# AUX_TDC register map
Vendor: Texas Instruments
Peripheral module from a debugger description file (folder CC26x4).
Registers are 32-bit, access per field, reset 0x0 unless marked. A register's access mark holds for its fields unless they carry their own. Offsets are as the file gives them; lines under a group give offsets from that group; [hi:lo] are bit positions; {n}, {i} and the like mark numbered series; 'fields as' and 'values as' point back to an identical list; <NAME> marks a mode.

## AUX_TDC — AUX Time To Digital Converter (AUX_TDC) is used to measure the time between two events with high resolution. AUX_TDC consists of a state machine that operates at AUX bus rate and an asynchronous fast-counter which is clocked by the TDC clock. DDI_0_OSC:CTL0.ACLK_TDC_SRC_SEL configures TDC clock source. The fast-counter counts on both edges of the TDC clock to double the resolution. See the Technical Reference Manual for event timing requirements.
0x00 CTL — Control
  [1:0] CMD wo — TDC commands.
    3=ABORT (Force TDC state machine back to IDLE state. Never write this command while AUX_TDC:STAT.STATE equals CLR_CNT or WAIT_CLR_CNT_DONE.); 2=RUN (Asynchronous counter start. The counter starts to count when the start event is high. To achieve precise edge-to-edge measurements you must ensure that the start event is low for at least 420 ns after you write this command.); 1=RUN_SYNC_START (Synchronous counter start. The counter looks for the opposite edge of the selected start event before it starts to count when the selected edge occurs. This guarantees an edge-triggered start and is recommended for frequency measurements.); 0=CLR_RESULT (Clear STAT.SAT, STAT.DONE, and RESULT.VALUE. This is not needed as prerequisite for a measurement. Reliable clear is only guaranteed from IDLE state.)
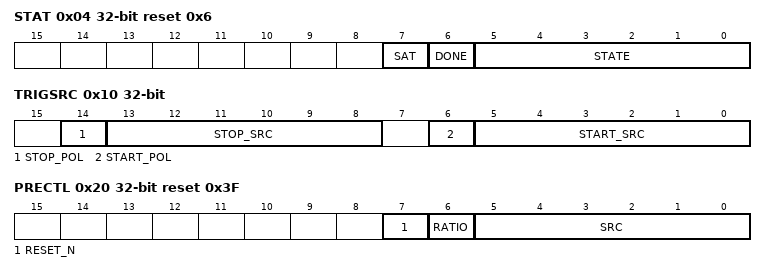
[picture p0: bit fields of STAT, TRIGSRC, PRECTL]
0x04 STAT ro reset 0x6 — Status
  [7] SAT — TDC measurement saturation flag. 0: Conversion has not saturated. 1: Conversion stopped due to saturation. This field is cleared when a new measurement is started or when CLR_RESULT is written to CTL.CMD.
  [6] DONE — TDC measurement complete flag. 0: TDC measurement has not yet completed. 1: TDC measurement has completed. This field clears when a new TDC measurement starts or when you write CLR_RESULT to CTL.CMD.
  [5:0] STATE — TDC state machine status.
    46=FORCE_STOP (Current state is TDC_FORCESTOP. You wrote ABORT to CTL.CMD to abort the TDC measurement.); 30=START_FALL (Current state is TDC_WAIT_STARTFALL. The fast-counter circuit waits for a falling edge on the start event.); 22=WAIT_CLR_CNT_DONE (Current state is TDC_STATE_WAIT_CLRCNT_DONE. The state machine waits for fast-counter circuit to finish reset.); 15=POR (Current state is TDC_STATE_POR. This is the reset state.); 14=GET_RESULT (Current state is TDC_STATE_GETRESULTS. The state machine copies the counter value from the fast-counter circuit.); 12=WAIT_STOP_CNTDWN (Current state is TDC_STATE_WAIT_STOPCNTDOWN. The fast-counter circuit looks for the stop condition. It will ignore a number of stop events configured in TRIGCNTLOAD.CNT.); 8=WAIT_STOP (Current state is TDC_STATE_WAIT_STOP. The state machine waits for the fast-counter circuit to stop.); 7=CLR_CNT (Current state is TDC_STATE_CLRCNT. The fast-counter circuit is reset.); 6=IDLE (Current state is TDC_STATE_IDLE. This is the default state after reset and abortion. State will change when you write CTL.CMD to either RUN_SYNC_START or RUN.); 4=WAIT_START_STOP_CNT_EN (Current state is TDC_STATE_WAIT_STARTSTOPCNTEN. The fast-counter circuit looks for the start condition. The state machine waits for the fast-counter to increment.); 0=WAIT_START (Current state is TDC_STATE_WAIT_START. The fast-counter circuit looks for the start condition. The state machine waits for the fast-counter to increment.)
0x08 RESULT ro reset 0x2 — Result Result of last TDC conversion.
  [24:0] VALUE — TDC conversion result. The result of the TDC conversion is given in number of clock edges of the clock source selected in DDI_0_OSC:CTL0.ACLK_TDC_SRC_SEL. Both rising and falling edges are counted. If TDC counter saturates, VALUE is slightly higher than SATCFG.LIMIT, as it takes a non-zero time to stop the measurement. Hence, the maximum value of this field becomes slightly higher than 2^24 if you configure SATCFG.LIMIT to R24.
0x0C SATCFG reset 0xF — Saturation Configuration
  [3:0] LIMIT rw — Saturation limit. The flag STAT.SAT is set when the TDC counter saturates. Values not enumerated are not supported
    {v}=R{v+9} (Result bit {v+9}: TDC conversion saturates and stops when RESULT.VALUE[{v+9}] is set.) (v=3..15)
0x10 TRIGSRC — Trigger Source Select source and polarity for TDC start and stop events. See the Technical Reference Manual for event timing requirements.
  [14] STOP_POL rw — Polarity of stop source. Change only while STAT.STATE is IDLE.
    1=LOW (TDC conversion stops when low level is detected.); 0=HIGH (TDC conversion stops when high level is detected.)
  [13:8] STOP_SRC rw — Select stop source from the asynchronous AUX event bus. Change only while STAT.STATE is IDLE.
    63=NO_EVENT; 62=AUX_TDC_PRE (Select TDC Prescaler event which is generated by configuration of PRECTL.); 61=AUX_SMPH_AUTOTAKE_DONE (AUX_EVCTL:EVSTAT3.AUX_SMPH_AUTOTAKE_DONE); 60=AUX_ADC_FIFO_NOT_EMPTY (AUX_EVCTL:EVSTAT3.AUX_ADC_FIFO_NOT_EMPTY); 59=AUX_ADC_FIFO_ALMOST_FULL (AUX_EVCTL:EVSTAT3.AUX_ADC_FIFO_ALMOST_FULL); 58=AUX_ADC_IRQ (AUX_EVCTL:EVSTAT3.AUX_ADC_IRQ); 57=AUX_ADC_DONE (AUX_EVCTL:EVSTAT3.AUX_ADC_DONE); 56=AUX_ISRC_RESET_N (AUX_EVCTL:EVSTAT3.AUX_ISRC_RESET_N); 55=AUX_TDC_DONE (AUX_EVCTL:EVSTAT3.AUX_TDC_DONE); 54=AUX_TIMER0_EV (AUX_EVCTL:EVSTAT3.AUX_TIMER0_EV); 53=AUX_TIMER1_EV (AUX_EVCTL:EVSTAT3.AUX_TIMER1_EV); 52=AUX_TIMER2_PULSE (AUX_EVCTL:EVSTAT3.AUX_TIMER2_PULSE); {v}=AUX_TIMER2_EV{v-48} (AUX_EVCTL:EVSTAT3.AUX_TIMER2_EV{v-48}) (v=48..51); 47=AUX_COMPB (AUX_EVCTL:EVSTAT2.AUX_COMPB); 46=AUX_COMPA (AUX_EVCTL:EVSTAT2.AUX_COMPA); 45=MCU_OBSMUX1 (AUX_EVCTL:EVSTAT2.MCU_OBSMUX1); 44=MCU_OBSMUX0 (AUX_EVCTL:EVSTAT2.MCU_OBSMUX0); 43=MCU_EV (AUX_EVCTL:EVSTAT2.MCU_EV); 42=ACLK_REF (AUX_EVCTL:EVSTAT2.ACLK_REF); 41=VDDR_RECHARGE (AUX_EVCTL:EVSTAT2.VDDR_RECHARGE); 40=MCU_ACTIVE (AUX_EVCTL:EVSTAT2.MCU_ACTIVE); 39=PWR_DWN (AUX_EVCTL:EVSTAT2.PWR_DWN); 38=SCLK_LF (AUX_EVCTL:EVSTAT2.SCLK_LF); 37=AON_BATMON_TEMP_UPD (AUX_EVCTL:EVSTAT2.AON_BATMON_TEMP_UPD); 36=AON_BATMON_BAT_UPD (AUX_EVCTL:EVSTAT2.AON_BATMON_BAT_UPD); 35=AON_RTC_4KHZ (AUX_EVCTL:EVSTAT2.AON_RTC_4KHZ); 34=AON_RTC_CH2_DLY (AUX_EVCTL:EVSTAT2.AON_RTC_CH2_DLY); 33=AON_RTC_CH2 (AUX_EVCTL:EVSTAT2.AON_RTC_CH2); 32=MANUAL_EV (AUX_EVCTL:EVSTAT2.MANUAL_EV); {v}=AUXIO{v} (AUX_EVCTL:EVSTAT1.AUXIO{v}) (v=16..31); {v}=AUXIO{v} (AUX_EVCTL:EVSTAT0.AUXIO{v}) (v=0..15)
  [6] START_POL rw — Polarity of start source. Change only while STAT.STATE is IDLE.
    1=LOW (TDC conversion starts when low level is detected.); 0=HIGH (TDC conversion starts when high level is detected.)
  [5:0] START_SRC rw — Select start source from the asynchronous AUX event bus. Change only while STAT.STATE is IDLE.
    values as STOP_SRC
0x14 TRIGCNT — Trigger Counter Stop-counter control and status.
  [15:0] CNT rw — Number of stop events to ignore when AUX_TDC:TRIGCNTCFG.EN is 1. Read CNT to get the remaining number of stop events to ignore during a TDC measurement. Write CNT to update the remaining number of stop events to ignore during a TDC measurement. The TDC measurement ignores updates of CNT if there are no more stop events left to ignore. When AUX_TDC:TRIGCNTCFG.EN is 1, TRIGCNTLOAD.CNT is loaded into CNT at the start of the measurement.
0x18 TRIGCNTLOAD — Trigger Counter Load Stop-counter load.
  [15:0] CNT rw — Number of stop events to ignore when AUX_TDC:TRIGCNTCFG.EN is 1. To measure frequency of an event source: - Set start event equal to stop event. - Set CNT to number of periods to measure. Both 0 and 1 values measures a single event source period. To measure pulse width of an event source: - Set start event source equal to stop event source. - Select different polarity for start and stop event. - Set CNT to 0. To measure time from the start event to the Nth stop event when N > 1: - Select different start and stop event source. - Set CNT to (N-1). See the Technical Reference Manual for event timing requirements. When AUX_TDC:TRIGCNTCFG.EN is 1, CNT is loaded into TRIGCNT.CNT at the start of the measurement.
0x1C TRIGCNTCFG — Trigger Counter Configuration Stop-counter configuration.
  [0] EN rw — Enable stop-counter. 0: Disable stop-counter. 1: Enable stop-counter. Change only while STAT.STATE is IDLE.
0x20 PRECTL reset 0x3F — Prescaler Control The prescaler can be used to count events that are faster than the AUX bus rate. It can be used to: - count pulses on a specified event from the asynchronous event bus. - prescale a specified event from the asynchronous event bus. To use the prescaler output as an event source in TDC measurements you must set both TRIGSRC.START_SRC and TRIGSRC.STOP_SRC to AUX_TDC_PRE. It is recommended to use the prescaler when the signal frequency to measure exceeds 1/10th of the AUX bus rate.
  [7] RESET_N rw — Prescaler reset. 0: Reset prescaler. 1: Release reset of prescaler. AUX_TDC_PRE event becomes 0 when you reset the prescaler.
  [6] RATIO rw — Prescaler ratio. This controls how often the AUX_TDC_PRE event is generated by the prescaler.
    1=DIV64 (Prescaler divides input by 64. AUX_TDC_PRE event has a rising edge for every 64 rising edges of the input. AUX_TDC_PRE event toggles on every 32nd rising edge of the input.); 0=DIV16 (Prescaler divides input by 16. AUX_TDC_PRE event has a rising edge for every 16 rising edges of the input. AUX_TDC_PRE event toggles on every 8th rising edge of the input.)
  [5:0] SRC rw — Prescaler event source. Select an event from the asynchronous AUX event bus to connect to the prescaler input. Configure only while RESET_N is 0.
    63=NO_EVENT; 61=AUX_SMPH_AUTOTAKE_DONE (AUX_EVCTL:EVSTAT3.AUX_SMPH_AUTOTAKE_DONE); 60=AUX_ADC_FIFO_NOT_EMPTY (AUX_EVCTL:EVSTAT3.AUX_ADC_FIFO_NOT_EMPTY); 59=AUX_ADC_FIFO_ALMOST_FULL (AUX_EVCTL:EVSTAT3.AUX_ADC_FIFO_ALMOST_FULL); 58=AUX_ADC_IRQ (AUX_EVCTL:EVSTAT3.AUX_ADC_IRQ); 57=AUX_ADC_DONE (AUX_EVCTL:EVSTAT3.AUX_ADC_DONE); 56=AUX_ISRC_RESET_N (AUX_EVCTL:EVSTAT3.AUX_ISRC_RESET_N); 55=AUX_TDC_DONE (AUX_EVCTL:EVSTAT3.AUX_TDC_DONE); 54=AUX_TIMER0_EV (AUX_EVCTL:EVSTAT3.AUX_TIMER0_EV); 53=AUX_TIMER1_EV (AUX_EVCTL:EVSTAT3.AUX_TIMER1_EV); 52=AUX_TIMER2_PULSE (AUX_EVCTL:EVSTAT3.AUX_TIMER2_PULSE); {v}=AUX_TIMER2_EV{v-48} (AUX_EVCTL:EVSTAT3.AUX_TIMER2_EV{v-48}) (v=48..51); 47=AUX_COMPB (AUX_EVCTL:EVSTAT2.AUX_COMPB); 46=AUX_COMPA (AUX_EVCTL:EVSTAT2.AUX_COMPA); 45=MCU_OBSMUX1 (AUX_EVCTL:EVSTAT2.MCU_OBSMUX1); 44=MCU_OBSMUX0 (AUX_EVCTL:EVSTAT2.MCU_OBSMUX0); 43=MCU_EV (AUX_EVCTL:EVSTAT2.MCU_EV); 42=ACLK_REF (AUX_EVCTL:EVSTAT2.ACLK_REF); 41=VDDR_RECHARGE (AUX_EVCTL:EVSTAT2.VDDR_RECHARGE); 40=MCU_ACTIVE (AUX_EVCTL:EVSTAT2.MCU_ACTIVE); 39=PWR_DWN (AUX_EVCTL:EVSTAT2.PWR_DWN); 38=SCLK_LF (AUX_EVCTL:EVSTAT2.SCLK_LF); 37=AON_BATMON_TEMP_UPD (AUX_EVCTL:EVSTAT2.AON_BATMON_TEMP_UPD); 36=AON_BATMON_BAT_UPD (AUX_EVCTL:EVSTAT2.AON_BATMON_BAT_UPD); 35=AON_RTC_4KHZ (AUX_EVCTL:EVSTAT2.AON_RTC_4KHZ); 34=AON_RTC_CH2_DLY (AUX_EVCTL:EVSTAT2.AON_RTC_CH2_DLY); 33=AON_RTC_CH2 (AUX_EVCTL:EVSTAT2.AON_RTC_CH2); 32=MANUAL_EV (AUX_EVCTL:EVSTAT2.MANUAL_EV); {v}=AUXIO{v} (AUX_EVCTL:EVSTAT1.AUXIO{v}) (v=16..31); {v}=AUXIO{v} (AUX_EVCTL:EVSTAT0.AUXIO{v}) (v=0..15)
0x24 PRECNTR — Prescaler Counter
  [15:0] CNT rw — Prescaler counter value. Write a value to CNT to capture the value of the 16-bit prescaler counter into CNT. Read CNT to get the captured value. The read value gets 1 LSB uncertainty if the event source level rises when you release the reset. The read value gets 1 LSB uncertainty if the event source level rises when you capture the prescaler counter. Please note the following: - The prescaler counter is reset to 2 by PRECTL.RESET_N. - The captured value is 2 when the number of rising edges on prescaler input is less than 3. Otherwise, captured value equals number of event pulses - 1.
